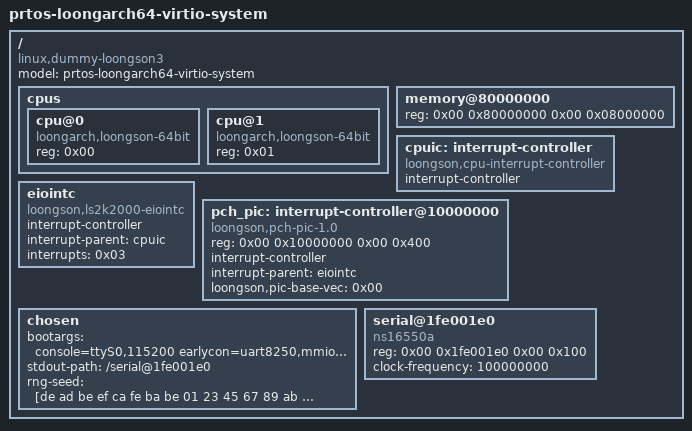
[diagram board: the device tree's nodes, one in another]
/dts-v1/;

/ {
	#address-cells = <0x02>;
	#size-cells = <0x02>;
	compatible = "linux,dummy-loongson3";
	model = "prtos-loongarch64-virtio-system";

	cpus {
		#address-cells = <0x01>;
		#size-cells = <0x00>;

		cpu@0 {
			device_type = "cpu";
			compatible = "loongarch,loongson-64bit";
			reg = <0x00>;
		};

		cpu@1 {
			device_type = "cpu";
			compatible = "loongarch,loongson-64bit";
			reg = <0x01>;
		};
	};

	memory@80000000 {
		device_type = "memory";
		reg = <0x00 0x80000000 0x00 0x08000000>;
	};

	cpuic: interrupt-controller {
		compatible = "loongson,cpu-interrupt-controller";
		#interrupt-cells = <0x01>;
		interrupt-controller;
	};

	eiointc: eiointc {
		compatible = "loongson,ls2k2000-eiointc";
		#interrupt-cells = <0x01>;
		interrupt-controller;
		interrupt-parent = <&cpuic>;
		interrupts = <0x03>;
	};

	pch_pic: interrupt-controller@10000000 {
		compatible = "loongson,pch-pic-1.0";
		reg = <0x00 0x10000000 0x00 0x400>;
		#interrupt-cells = <0x02>;
		interrupt-controller;
		interrupt-parent = <&eiointc>;
		loongson,pic-base-vec = <0x00>;
	};

	chosen {
		bootargs = "console=ttyS0,115200 earlycon=uart8250,mmio,0x1fe001e0 mem=128M@0x80000000 i8042.noaux i8042.nokbd i8042.nopnp nokaslr nohz=off highres=off quiet loglevel=0";
		stdout-path = "/serial@1fe001e0";
		rng-seed = [de ad be ef ca fe ba be 01 23 45 67 89 ab cd ef
		            fe dc ba 98 76 54 32 10 a0 b1 c2 d3 e4 f5 06 17
		            28 39 4a 5b 6c 7d 8e 9f 10 21 32 43 54 65 76 87
		            98 a9 ba cb dc ed fe 0f 11 22 33 44 55 66 77 88];
	};

	serial@1fe001e0 {
		compatible = "ns16550a";
		reg = <0x00 0x1fe001e0 0x00 0x100>;
		clock-frequency = <100000000>;
	};
};
